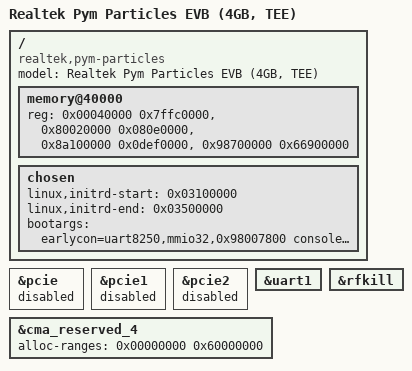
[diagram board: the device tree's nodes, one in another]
// SPDX-License-Identifier: (GPL-2.0-or-later OR BSD-2-Clause)
/*
 * Copyright (c) 2019-2024 Realtek Semiconductor Corp.
 */

/dts-v1/;

#include "rtd1319b-pymparticles.dtsi"

/ {
	compatible = "realtek,pym-particles", "realtek,rtd1319b";
	model = "Realtek Pym Particles EVB (4GB, TEE)";

	memory@40000 {
		device_type = "memory";
		reg = <0x00040000 0x7ffc0000>,
		      <0x80020000 0x080e0000>,
		      <0x8a100000 0x0def0000>,
		      <0x98700000 0x66900000>; /* 4 GB */
	};

	chosen {
		linux,initrd-start = <0x03100000>;
		linux,initrd-end = <0x03500000>;
		bootargs = "earlycon=uart8250,mmio32,0x98007800 console=ttyS0,460800 init=/init loop.max_part=7 androidboot.storage=emmc androidboot.hardware=hank";
	};
};

&pcie {
	status = "disabled";
};

&pcie1 {
	status = "disabled";
};

&pcie2 {
	status = "disabled";
};

&uart1 {
	status = "okay";
};

&rfkill {
	status = "okay";
};

&cma_reserved_4 {
	alloc-ranges=<0x00000000 0x60000000>;
};
